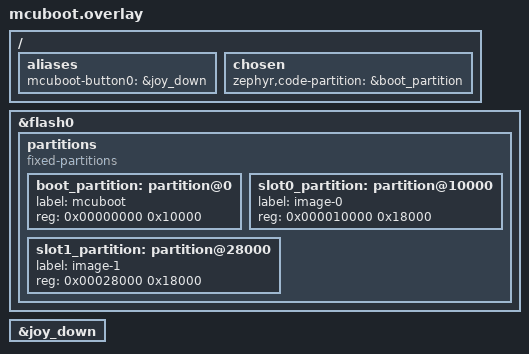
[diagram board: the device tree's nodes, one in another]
/ {
	aliases {
		mcuboot-button0 = &joy_down;
	};

	chosen {
		zephyr,code-partition = &boot_partition;
	};
};

&flash0 {
	partitions {
		compatible = "fixed-partitions";
		#address-cells = <1>;
		#size-cells = <1>;

		boot_partition: partition@0 {
			label = "mcuboot";
			reg = <0x00000000 0x10000>;
		};
		slot0_partition: partition@10000 {
			label = "image-0";
			reg = <0x000010000 0x18000>;
		};
		slot1_partition: partition@28000 {
			label = "image-1";
			reg = <0x00028000 0x18000>;
		};
	};
};

&joy_down {
	status = "okay";
};
